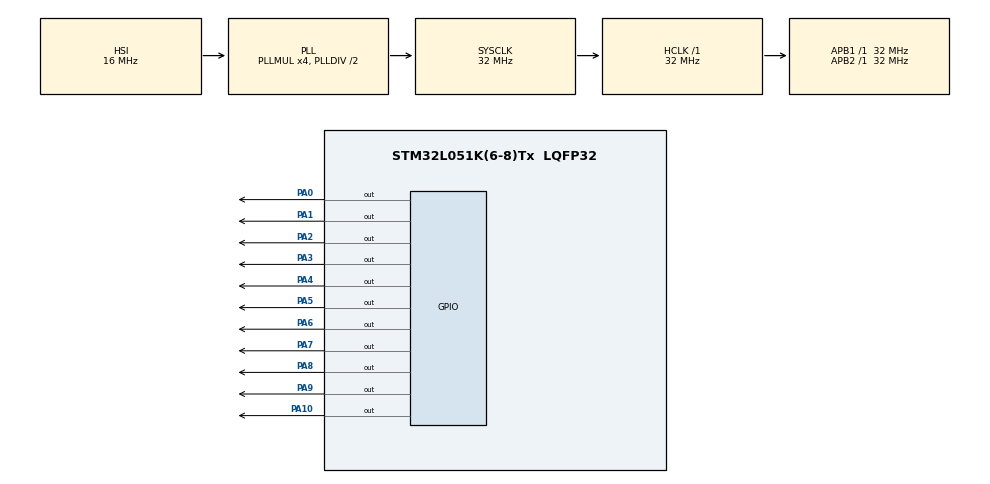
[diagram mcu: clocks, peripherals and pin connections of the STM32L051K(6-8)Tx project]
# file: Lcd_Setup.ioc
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Mcu.Family=STM32L0
Mcu.Name=STM32L051K(6-8)Tx
Mcu.Package=LQFP32
PA0.Signal=GPIO_Output
PA1.Signal=GPIO_Output
PA10.Signal=GPIO_Output
PA13.Mode=Serial_Wire
PA13.Signal=SYS_SWDIO
PA14.Mode=Serial_Wire
PA14.Signal=SYS_SWCLK
PA2.Signal=GPIO_Output
PA3.Signal=GPIO_Output
PA4.Signal=GPIO_Output
PA5.Signal=GPIO_Output
PA6.Signal=GPIO_Output
PA7.Signal=GPIO_Output
PA8.Signal=GPIO_Output
PA9.Signal=GPIO_Output
ProjectManager.HeapSize=0x200
ProjectManager.StackSize=0x400
ProjectManager.TargetToolchain=MDK-ARM V5.32
RCC.AHBFreq_Value=32000000
RCC.APB1Freq_Value=32000000
RCC.APB1TimFreq_Value=32000000
RCC.APB2Freq_Value=32000000
RCC.APB2TimFreq_Value=32000000
RCC.HCLKFreq_Value=32000000
RCC.HSI16_VALUE=16000000
RCC.HSI_VALUE=16000000
RCC.LSE_VALUE=32768
RCC.MSI_VALUE=2097000
RCC.PLLMUL=RCC_PLLMUL_4
RCC.SYSCLKFreq_VALUE=32000000
RCC.SYSCLKSource=RCC_SYSCLKSOURCE_PLLCLK
RCC.VCOOutputFreq_Value=64000000
board=custom

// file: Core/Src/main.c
/* USER CODE BEGIN Header */
/**
  ******************************************************************************
  * @file           : main.c
  * @brief          : Main program body
  ******************************************************************************
  * @attention
  *
  * Copyright (c) 2022 STMicroelectronics.
  * All rights reserved.
  *
  * This software is licensed under terms that can be found in the LICENSE file
  * in the root directory of this software component.
  * If no LICENSE file comes with this software, it is provided AS-IS.
  *
  ******************************************************************************
  */
/* USER CODE END Header */
#include "main.h"

void SystemClock_Config(void);
static void MX_GPIO_Init(void);

int main(void)
{

  /* MCU Configuration--------------------------------------------------------*/

  /* Reset of all peripherals, Initializes the Flash interface and the Systick. */
  HAL_Init();

  /* Configure the system clock */
  SystemClock_Config();

  /* Initialize all configured peripherals */
  MX_GPIO_Init();
  /* USER CODE BEGIN 2 */
		Lcd_Init();
		Lcd_Init();
		Lcd_Init();
  /* USER CODE END 2 */

  /* Infinite loop */
  while (1)
  {

  }
}

void SystemClock_Config(void)
{
  RCC_OscInitTypeDef RCC_OscInitStruct = {0};
  RCC_ClkInitTypeDef RCC_ClkInitStruct = {0};

  /** Configure the main internal regulator output voltage
  */
  __HAL_PWR_VOLTAGESCALING_CONFIG(PWR_REGULATOR_VOLTAGE_SCALE1);
  /** Initializes the RCC Oscillators according to the specified parameters
  * in the RCC_OscInitTypeDef structure.
  */
  RCC_OscInitStruct.OscillatorType = RCC_OSCILLATORTYPE_HSI;
  RCC_OscInitStruct.HSIState = RCC_HSI_ON;
  RCC_OscInitStruct.HSICalibrationValue = RCC_HSICALIBRATION_DEFAULT;
  RCC_OscInitStruct.PLL.PLLState = RCC_PLL_ON;
  RCC_OscInitStruct.PLL.PLLSource = RCC_PLLSOURCE_HSI;
  RCC_OscInitStruct.PLL.PLLMUL = RCC_PLLMUL_4;
  RCC_OscInitStruct.PLL.PLLDIV = RCC_PLLDIV_2;
  if (HAL_RCC_OscConfig(&RCC_OscInitStruct) != HAL_OK)
  {
    Error_Handler();
  }
  /** Initializes the CPU, AHB and APB buses clocks
  */
  RCC_ClkInitStruct.ClockType = RCC_CLOCKTYPE_HCLK|RCC_CLOCKTYPE_SYSCLK
                              |RCC_CLOCKTYPE_PCLK1|RCC_CLOCKTYPE_PCLK2;
  RCC_ClkInitStruct.SYSCLKSource = RCC_SYSCLKSOURCE_PLLCLK;
  RCC_ClkInitStruct.AHBCLKDivider = RCC_SYSCLK_DIV1;
  RCC_ClkInitStruct.APB1CLKDivider = RCC_HCLK_DIV1;
  RCC_ClkInitStruct.APB2CLKDivider = RCC_HCLK_DIV1;

  if (HAL_RCC_ClockConfig(&RCC_ClkInitStruct, FLASH_LATENCY_1) != HAL_OK)
  {
    Error_Handler();
  }
}

static void MX_GPIO_Init(void)
{
  GPIO_InitTypeDef GPIO_InitStruct = {0};

  /* GPIO Ports Clock Enable */
  __HAL_RCC_GPIOA_CLK_ENABLE();

  /*Configure GPIO pin Output Level */
  HAL_GPIO_WritePin(GPIOA, GPIO_PIN_0|GPIO_PIN_1|GPIO_PIN_2|GPIO_PIN_3
                          |GPIO_PIN_4|GPIO_PIN_5|GPIO_PIN_6|GPIO_PIN_7
                          |GPIO_PIN_8|GPIO_PIN_9|GPIO_PIN_10, GPIO_PIN_RESET);

  /*Configure GPIO pins : PA0 PA1 PA2 PA3
                           PA4 PA5 PA6 PA7
                           PA8 PA9 PA10 */
  GPIO_InitStruct.Pin = GPIO_PIN_0|GPIO_PIN_1|GPIO_PIN_2|GPIO_PIN_3
                          |GPIO_PIN_4|GPIO_PIN_5|GPIO_PIN_6|GPIO_PIN_7
                          |GPIO_PIN_8|GPIO_PIN_9|GPIO_PIN_10;
  GPIO_InitStruct.Mode = GPIO_MODE_OUTPUT_PP;
  GPIO_InitStruct.Pull = GPIO_NOPULL;
  GPIO_InitStruct.Speed = GPIO_SPEED_FREQ_LOW;
  HAL_GPIO_Init(GPIOA, &GPIO_InitStruct);

}

void Error_Handler(void)
{
  __disable_irq();
  while (1)
  {
  }
}
